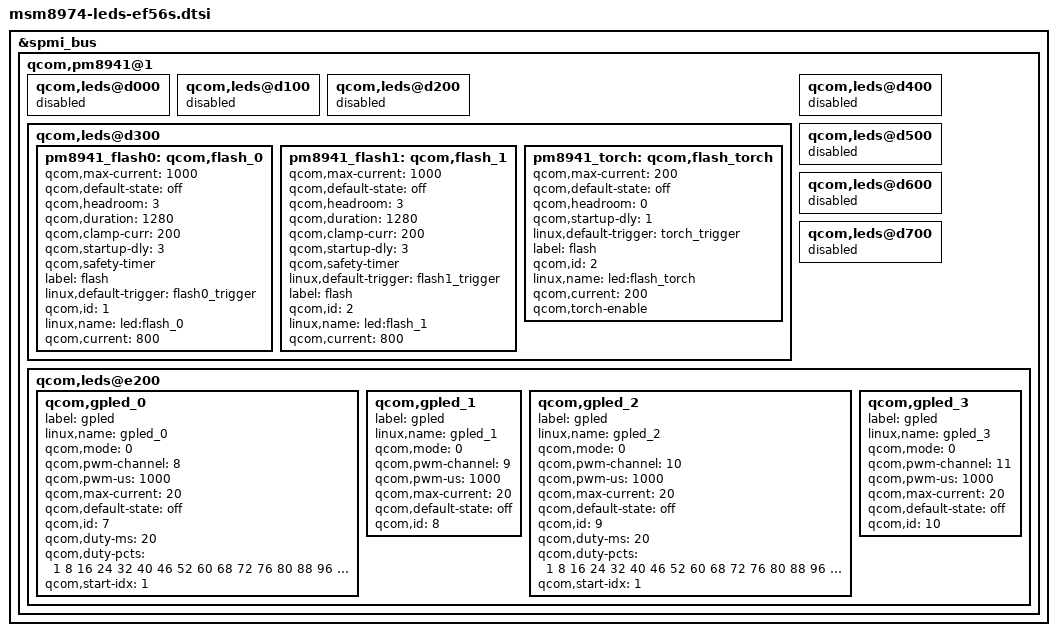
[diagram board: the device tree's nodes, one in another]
/*
 * Copyright (c) 2012-2013, The Linux Foundation. All rights reserved.
 *
 * This program is free software; you can redistribute it and/or modify
 * it under the terms of the GNU General Public License version 2 and
 * only version 2 as published by the Free Software Foundation.
 *
 * This program is distributed in the hope that it will be useful,
 * but WITHOUT ANY WARRANTY; without even the implied warranty of
 * MERCHANTABILITY or FITNESS FOR A PARTICULAR PURPOSE.  See the
 * GNU General Public License for more details.
 */

&spmi_bus {
	qcom,pm8941@1 {
		qcom,leds@d000 {
			status = "disabled";			
		};

		qcom,leds@d100 {
			status = "disabled";
		};

		qcom,leds@d200 {
			status = "disabled";
		};

		qcom,leds@d300 {
			status = "okay";
			pm8941_flash0: qcom,flash_0 {
				qcom,max-current = <1000>;
				qcom,default-state = "off";
				qcom,headroom = <3>;
				qcom,duration = <1280>;
				qcom,clamp-curr = <200>;
				qcom,startup-dly = <3>;
				qcom,safety-timer;
				label = "flash";
				linux,default-trigger =
					"flash0_trigger";
				qcom,id = <1>;
				linux,name = "led:flash_0";
				qcom,current = <800>;//625>;
			};

			pm8941_flash1: qcom,flash_1 {
				qcom,max-current = <1000>;
				qcom,default-state = "off";
				qcom,headroom = <3>;
				qcom,duration = <1280>;
				qcom,clamp-curr = <200>;
				qcom,startup-dly = <3>;
				qcom,safety-timer;
				linux,default-trigger =
					"flash1_trigger";
				label = "flash";
				qcom,id = <2>;
				linux,name = "led:flash_1";
				qcom,current = <800>;//<625>;
			};

			pm8941_torch: qcom,flash_torch {
				qcom,max-current = <200>;
				qcom,default-state = "off";
				qcom,headroom = <0>;
				qcom,startup-dly = <1>;
				linux,default-trigger =
					"torch_trigger";
				label = "flash";
				qcom,id = <2>;
				linux,name = "led:flash_torch";
				qcom,current = <200>;
				qcom,torch-enable;
		};
		};

		qcom,leds@d400 {
			status = "disabled";
		};

		qcom,leds@d500 {
			status = "disabled";
		};

		qcom,leds@d600 {
			status = "disabled";
		};

		qcom,leds@d700 {
			status = "disabled";
		};
		
/* p11309 From Qualcomm Patch - 2013.03.27   */
		qcom,leds@e200 {
			status = "okay";
			qcom,gpled_0 {
				label = "gpled";
				linux,name = "gpled_0";
				qcom,mode = <0>;
				qcom,pwm-channel = <8>;
				qcom,pwm-us = <1000>;
				qcom,max-current = <20>;
				qcom,default-state = "off";
				qcom,id = <7>;		
				qcom,duty-ms = <20>;
				qcom,duty-pcts = <
					1 8 16 24 32 40 46 52 60 68
					72 76 80 88 96 100 100 95 88 78
					70 66 58 50 42 34 26 14 6 1	>;
				qcom,start-idx = <1>;
				/*linux,default-trigger =	"battery-charging";*/
			};
			
			qcom,gpled_1 {
				label = "gpled";
				linux,name = "gpled_1";
				qcom,mode = <0>;
				qcom,pwm-channel = <9>;
				qcom,pwm-us = <1000>;
				qcom,max-current = <20>;
				qcom,default-state = "off";
				qcom,id = <8>;							
			};		
			
			qcom,gpled_2 {
				label = "gpled";
				linux,name = "gpled_2";
				qcom,mode = <0>;
				qcom,pwm-channel = <10>;
				qcom,pwm-us = <1000>;
				qcom,max-current = <20>;
				qcom,default-state = "off";
				qcom,id = <9>;			
				qcom,duty-ms = <20>;	
				qcom,duty-pcts = <
					1 8 16 24 32 40 46 52 60 68
					72 76 80 88 96 100 100 95 88 78
					70 66 58 50 42 34 26 14 6 1	>;
				qcom,start-idx = <1>;
				/*linux,default-trigger = "battery-full";*/
			};		
			
			qcom,gpled_3 {
				label = "gpled";
				linux,name = "gpled_3";
				qcom,mode = <0>;
				qcom,pwm-channel = <11>;
				qcom,pwm-us = <1000>;
				qcom,max-current = <20>;
				qcom,default-state = "off";
				qcom,id = <10>;				
			};
		};
	};
};

